# S6E2D5xJ register map
Vendor: Cypress; File version: 2.1
CPU: CM4 r0p1, little endian, MPU, FPU, 4 interrupt priority bits
Registers are 32-bit, read-write, reset 0x0 unless marked. A register's access mark holds for its fields unless they carry their own. Offsets are from the block's base; [hi:lo] are bit positions.

## CANPRES — CAN Prescaler Register
Base 0x40037000
0x00 CANPRE 8-bit reset 0xB — CAN Prescaler Register [BHW]
  [3:0] CANPRE — CAN prescaler setting bits

## CRC — CRC Registers
Base 0x40039000
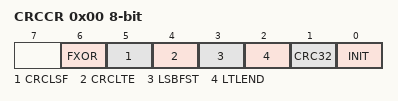
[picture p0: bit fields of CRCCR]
0x00 CRCCR 8-bit — CRC Control Register [BHW]
  [6] FXOR — Final XOR control bit
  [5] CRCLSF — CRC result bit-order setting bit
  [4] CRCLTE — CRC result byte-order setting bit
  [3] LSBFST — Bit-order setting bit
  [2] LTLEND — Byte-order setting bit
  [1] CRC32 — CRC mode selection bit
  [0] INIT — Initialization bit
0x04 CRCINIT reset 0xFFFFFFFF — Initial Value Register [BHW]
  [31:0] D — Initial value
0x08 CRCIN — Input Data Register [BHW]
  [31:0] D — Input data
0x0C CRCR ro reset 0xFFFFFFFF — CRC Register [BHW]
  [31:0] D — CRC Data

## WC — Watch Counter
Base 0x4003A000
0x00 WCRD 8-bit ro — Watch Counter Read Register [BHW]
  [5:0] CTR — Counter read bits
0x01 WCRL 8-bit — Watch Counter Reload Register [BHW]
  [5:0] RLC — Counter reload value setting bits
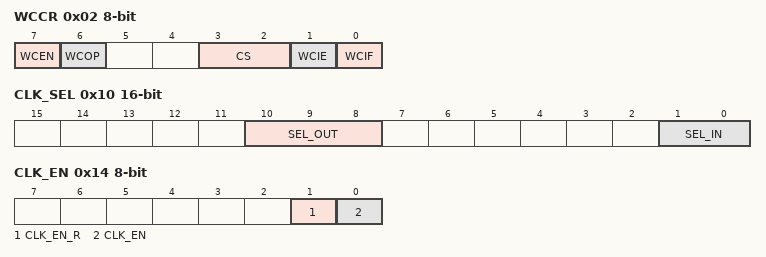
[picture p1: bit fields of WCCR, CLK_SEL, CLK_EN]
0x02 WCCR 8-bit — Watch Counter Control Register [BHW]
  [7] WCEN — Watch counter operation enable bit
  [6] WCOP ro — Watch counter operating state flag
  [3:2] CS — Count clock select bits
  [1] WCIE — Interrupt request enable bit
  [0] WCIF — Interrupt request flag bit
0x10 CLK_SEL 16-bit — Clock Selection Register [BHW]
  [10:8] SEL_OUT — Output clock selection bit
  [1:0] SEL_IN — Input clock selection bit
0x14 CLK_EN 8-bit — Division Clock Enable Register [BHW]
  [1] CLK_EN_R — Division clock enable read bit
  [0] CLK_EN — Division clock enable bit

## LSCRP — Low-speed CR Prescaler
Base 0x4003C000
0x00 LCR_PRSLD 8-bit — Low-speed CR Prescaler Control Register [BHW]
  [5:0] LCR_PRSLD — Low-speed CR Prescaler Load

## I2SPRE — I2S Clock Generation
Base 0x4003D000
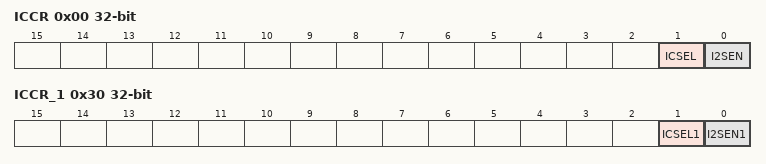
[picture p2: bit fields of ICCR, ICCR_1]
0x00 ICCR — I2S Clock Control Register [BHW]
  [1] ICSEL — I2S clock selection bit
  [0] I2SEN — I2S clock output enable bit
0x04 IPCR1 — I2S-PLL Control Register 1 [BHW]
  [0] IPLLEN — I2S-PLL oscillation enable bit
0x08 IPCR2 — I2S-PLL Control Register 2 [BHW]
  [2:0] IPOWT — I2S-PLL oscillation stabilization wait time setting bits
0x0C IPCR3 reset 0x1 — I2S-PLL Control Register 3 [BHW]
  [4:0] IPLLK — Frequency division ratio (K) setting bits of the I2S-PLL clock
0x10 IPCR4 reset 0x1F — I2S-PLL Control Register 4 [BHW]
  [6:0] IPLLN — Frequency division ratio (N) setting bits of the I2S-PLL clock
0x14 IP_STR ro — I2S-PLL Status Register [BHW]
  [0] IPRDY — I2S-PLL oscillation stabilization bit
0x18 IPINT_ENR — I2S-PLL Interrupt Factor Enable Register [BHW]
  [0] IPCSE — I2S-PLL oscillation stabilization wait complete interrupt enable bit
0x1C IPINT_CLR wo — I2S-PLL Interrupt Factor Status Register [BHW]
  [0] IPCSC — I2S-PLL interrupt factor status bit
0x20 IPINT_STR ro — I2S-PLL Interrupt Factor Clear Register [BHW]
  [0] IPCSI — I2S-PLL oscillation stabilization interrupt factor clear bit
0x24 IPCR5 reset 0x18 — I2S-PLL Control Register 5 [BHW]
  [6:0] IPLLM — Frequency division ratio (M) setting bits of the I2S-PLL clock
0x30 ICCR_1 — I2S Clock Control Register [BHW]
  [1] ICSEL1 — I2S clock selection bit
  [0] I2SEN1 — I2S clock output enable bit
0x34 IPCR5_1 reset 0x18 — I2S-PLL Control Register 5 [BHW]
  [6:0] IPLLM1 — Frequency division ratio (M) setting bits of the I2S-PLL clock

## GDCPRE — GDC Prescaler
Base 0x4003D100
0x00 GCCR 8-bit — GSS Clock Control Register [BHW]
  [0] GSSEN — GSS clock output enable/disable setting bit
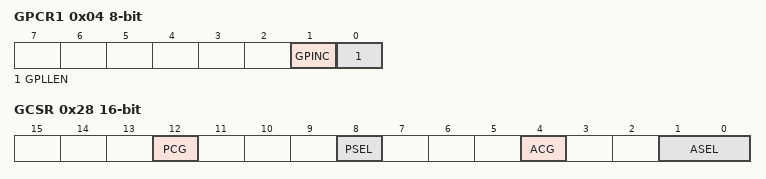
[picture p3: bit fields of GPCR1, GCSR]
0x04 GPCR1 8-bit — GSS PLL Control Register 1 [BHW]
  [1] GPINC — GDC PLL input clock selection bit
  [0] GPLLEN — GDC PLL enable/disable setting bit
0x08 GPCR2 8-bit — GSS PLL Control Register 2 [BHW]
  [2:0] GPOWT — PLL clock stabilization wait time set up bits
0x0C GPCR3 8-bit — GSS PLL Control Register 3 [BHW]
  [4:0] GPLLK — PLL input clock frequency division ratio setting bits
0x10 GPCR4 8-bit — GSS PLL Control Register 4 [BHW]
  [6:0] GPLLN — PLL feedback frequency division rasio seting bits
0x14 GP_STR 8-bit — GSS PLL Status Register [BHW]
  [0] GPRDY ro — GDC PLL status bit
0x18 GPINT_ENR 8-bit — GSS PLL Interrupt Enable Register [BHW]
  [0] GPCSE — PLL oscillation stabilization wait completion interrupt enable bit
0x1C GPINT_CLR 8-bit — GSS PLL Interrupt Clear Register [BHW]
  [0] GPCSC — GDC PLL oscillation stabilization wait completion interrupt clear bit
0x20 GPINT_STR 8-bit — GSS PLL Status Register [BHW]
  [0] GPCSI ro — GDC PLL oscillation stabilization wait completion interrupt status bit
0x28 GCSR 16-bit — GSS Clock Select Register [BHW]
  [12] PCG — HCLK Clock gating for Reference clock for Peripherals setting bit
  [8] PSEL — Peripheral clock for the GDC Sub system selection bit
  [4] ACG — Clock gating for Reference clock for GDC clock setting bit
  [1:0] ASEL — Reference clock for the GDC clock selection bits
0x2C GRCR 8-bit — GSS Reset Control Register [BHW]
  [0] RSTEN — Software reset for the GDC Sub system setting bit
0x30 GMCR 8-bit — GSS Mode Control Register [BHW]
  [0] TEN — PLL oscillation under case of TIMER mode control bit

## Notices in the file
Copyright (C) 2013-2016, Cypress Semiconductor Corporation or a
subsidiary of Cypress Semiconductor Corporation.  All rights reserved.
This software, including source code, documentation and related
materials ("Software"), is owned by Cypress Semiconductor Corporation or
one of its subsidiaries ("Cypress") and is protected by and subject to
worldwide patent protection (United States and foreign), United States
copyright laws and international treaty provisions. Therefore, you may use
this Software only as provided in the license agreement accompanying the
software package from which you obtained this Software ("EULA").
If no EULA applies, Cypress hereby grants you a personal, non-exclusive,
non-transferable license to copy, modify, and compile the
Software source code solely for use in connection with Cypress's
integrated circuit products.  Any reproduction, modification, translation,
compilation, or representation of this Software except as specified
above is prohibited without the express written permission of Cypress.
Disclaimer: THIS SOFTWARE IS PROVIDED AS-IS, WITH NO
WARRANTY OF ANY KIND, EXPRESS OR IMPLIED, INCLUDING,
BUT NOT LIMITED TO, NONINFRINGEMENT, IMPLIED
WARRANTIES OF MERCHANTABILITY AND FITNESS FOR A
PARTICULAR PURPOSE. Cypress reserves the right to make
changes to the Software without notice. Cypress does not assume any
liability arising out of the application or use of the Software or any
product or circuit described in the Software. Cypress does not
authorize its products for use in any products where a malfunction or
failure of the Cypress product may reasonably be expected to result in
significant property damage, injury or death ("High Risk Product"). By
including Cypress's product in a High Risk Product, the manufacturer
of such system or application assumes all risk of such use and in doing
so agrees to indemnify Cypress against all liability.
